# nrf7140_wificore register map
Vendor: Nordic Semiconductor; Series: nRF71; File version: 1
Registers are 32-bit, read-write, reset 0x0 unless marked. A register's access mark holds for its fields unless they carry their own. Offsets are from the block's base; [hi:lo] are bit positions; lines under a group give offsets from that group; {n}, {i} and the like mark numbered series.

## RPUMAC — WIFICore RPU MAC peripherals
Base 0x48080000
0x2000 CRYPTO_PERIP group — Unspecified
  0x00 MODE — CRYPTO PERIP MODE
    [0] CRYPTOMODE
      0=RX mode. Input is from MAC controller and output to EDC.; 1=TX mode. Input from EDC and output from MAC controller.
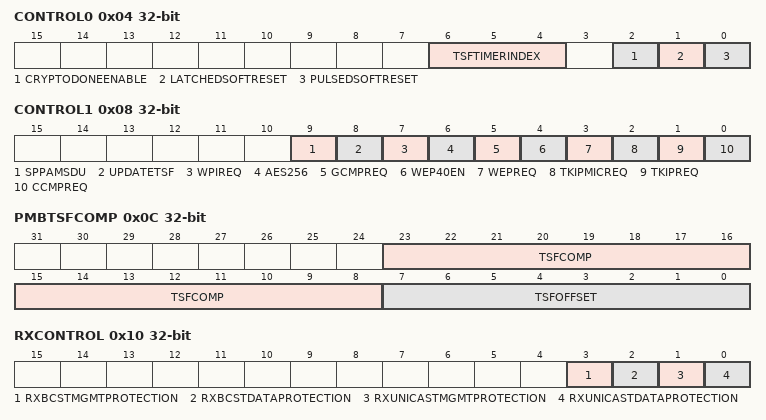
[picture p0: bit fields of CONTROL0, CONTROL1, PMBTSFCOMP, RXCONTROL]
  0x04 CONTROL0 — CRYPTO PERIP CONTROL 0
    [6:4] TSFTIMERINDEX — 64 bit timer index of hardware module. There are four 64 bit timers in and one of index is picked up for this.
    [2] CRYPTODONEENABLE — Enable EFS event CRYPTO_DONE_EVENT that indicates when the Crypto operation is complete.
      0=Disable CRYPTO_DONE_EVENT; 1=Enable CRYPTO_DONE_EVENT
    [1] LATCHEDSOFTRESET — Latched Crypto core soft reset.This bit is used to reset everything but the control registers.
      0=DeAssertResetToCore; 1=AssertResetToCore
    [0] PULSEDSOFTRESET — Self-clearing Crypto core soft reset.This bit is used to reset everything but the control registers.
      0=DeAssertResetToCore; 1=AssertResetToCore
  0x08 CONTROL1 ro — CRYPTO PERIP CONTROL 1
    [9] SPPAMSDU — Default value is zero, Set to 1 if SPP_A-MSDU_bit_setis requested by the receiver.
    [8] UPDATETSF — Set to 1 if HW is expected to modify TSF field in memcopy bytes. HW need read TSF value, compensate with COMP value and update in TSF field.
    [7] WPIREQ — WAPI operation
    [6] AES256 — Select AES key size.
      0=128Bits; 1=256Bits
    [5] GCMPREQ — GCMP operation
    [4] WEP40EN — WEP 40 operation
    [3] WEPREQ — WEP operation
    [2] TKIPMICREQ — TKIP Message Integrity Check (MIC) operation
    [1] TKIPREQ — TKIP operation
    [0] CCMPREQ — CCMP operation
  0x0C PMBTSFCOMP — PMB CRYPTO PERIP TSF COMP
    [23:8] TSFCOMP — Hw will add this value to TSF snapshot and update TSF value in probe response/beacon frame.
    [7:0] TSFOFFSET — TSF offset in memcopy stream.Must be set to a value greater than 1.
  0x10 RXCONTROL — CRYPTO PERIP RX CONTROL
    [3] RXBCSTMGMTPROTECTION — Set 1 to enable.
    [2] RXBCSTDATAPROTECTION — Set 1 to enable.
    [1] RXUNICASTMGMTPROTECTION — Set 1 to enable.
    [0] RXUNICASTDATAPROTECTION — Set 1 to enable.
  0x14 RXVECTORLENGTH — CRYPTO PERIP RX VECTOR LENGTH
    [7:0] RXVECTORLENGTH — RX vector length. Crypto hardware should bypass (memcopy) to output side without processing.
  0x18 RXFCSANDSTSLENGTH reset 0x5 — CRYPTO PERIP RX FCS AND STS LENGTH
    [7:0] RXFCSANDSTSLENGTH — Used to determine how many bytes need to be appended after decrypted payload.Note: When it's configured as 0, after payload bytes decrypted, controlstate machine will skip STEP_APPEND, do not appending any bytes.
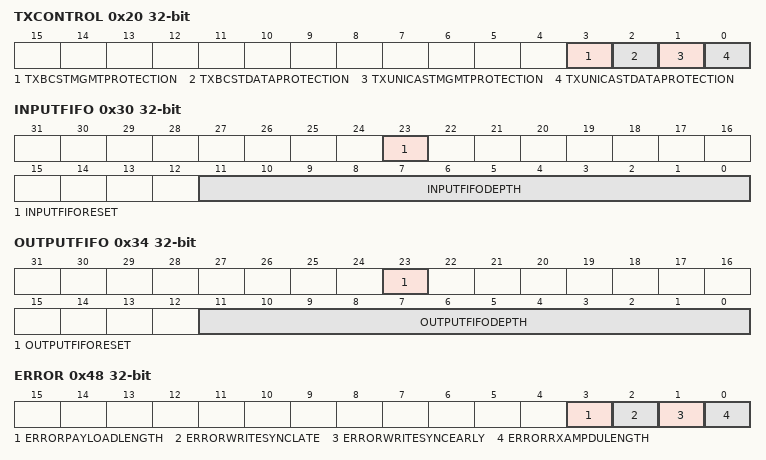
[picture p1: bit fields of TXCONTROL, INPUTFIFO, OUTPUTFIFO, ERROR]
  0x20 TXCONTROL — CRYPTO PERIP TX CONTROL
    [3] TXBCSTMGMTPROTECTION — Set 1 to enable.
    [2] TXBCSTDATAPROTECTION — Set 1 to enable.
    [1] TXUNICASTMGMTPROTECTION — Set 1 to enable.
    [0] TXUNICASTDATAPROTECTION — Set 1 to enable.
  0x24 TXVECTORLENGTH — CRYPTO PERIP TX VECTOR LENGTH
    [7:0] TXVECTORLENGTH — Valid range 0 to 255. Crypto hardware should bypass to output without processing.
  0x28 TXAMPDUSUBFRAMENUMBER reset 0x1 — CRYPTO PERIP TX AMPDU SUBFRAME NUMBER
    [6:0] TXAMPDUSUBFRAMENUMBER — Number of AMPDU subframes in current TX job.Minimum value is 1. Maximum value is 64.
  0x30 INPUTFIFO — CRYPTO PERIP INPUT FIFO
    [23] INPUTFIFORESET — Self-clearing input FIFO reset
      0=NoAction; 1=PerformReset
    [11:0] INPUTFIFODEPTH — Programmable FIFO depth.Note that DEPTH=0 will bypass the FIFO.Values of DEPTH greater than the physical FIFO depth will be saturated by hardware to the physical depth.
  0x34 OUTPUTFIFO — CRYPTO PERIP OUTPUT FIFO
    [23] OUTPUTFIFORESET — Self-clearing output FIFO reset
      0=NoAction; 1=PerformReset
    [11:0] OUTPUTFIFODEPTH — Programmable FIFO depth.Note that DEPTH=0 will bypass the FIFO.Values of DEPTH greater than the physical FIFO depth will be saturated by hardware to the physical depth.
  0x38 INPUTFIFOCOUNT ro — CRYPTO PERIP INPUT FIFO COUNT
    [11:0] INPUTFIFOCOUNT — Input FIFO data count.
  0x3C OUTPUTFIFOCOUNT ro — CRYPTO PERIP OUTPUT FIFO COUNT
    [11:0] OUTPUTFIFOCOUNT — Output FIFO data count.
  0x40 EVENTSTATUS — CRYPTO PERIP EVENT STATUS
    [0] CRYPTODONEEVENT — This bit is set to 1 when the Crypto operation is complete.Writing 1 sets this bit for test purposes.
  0x44 EVENTCLEAR — CRYPTO PERIP EVENT CLEAR
    [0] CRYPTODONECLEAR — Writing 1 to this bit sets CRYPTO_DONE and CRYPTO_DONE_EVENT to 0
  0x48 ERROR ro — CRYPTO PERIP ERROR
    [3] ERRORPAYLOADLENGTH — Received payload length is less than 0. Crypto will push valid=1 mask=1 eop=1 data=0 byte into the output, discard remaining inputs until sync flag received then start new job.
    [2] ERRORWRITESYNCLATE — TBus write sync flag appears later than expected. Crypto will set eop=1 on the last valid output byte, discard remaining inputs until sync flag received then start new job.
    [1] ERRORWRITESYNCEARLY — TBus write sync flag appears earlier than expected. Crypto will terminate current engine job if started, push valid=1 mask=1 eop=1 data=0 byte into the output, discard remaining inputs until sync flag received then start new job.
    [0] ERRORRXAMPDULENGTH — Received rx_ampdu_length is larger than 0xFFFF. Crypto will push valid=1 mask=1 eop=1 data=0 byte into the output, discard remaining inputs until sync flag received then start new job.
  0x4C ERRORCLEAR — CRYPTO PERIP ERROR CLEAR
    [0] CRYPTOPERIPERRORCLEAR — Writing 1 to this bit sets CRYPTO_PERIP_ERROR to 0
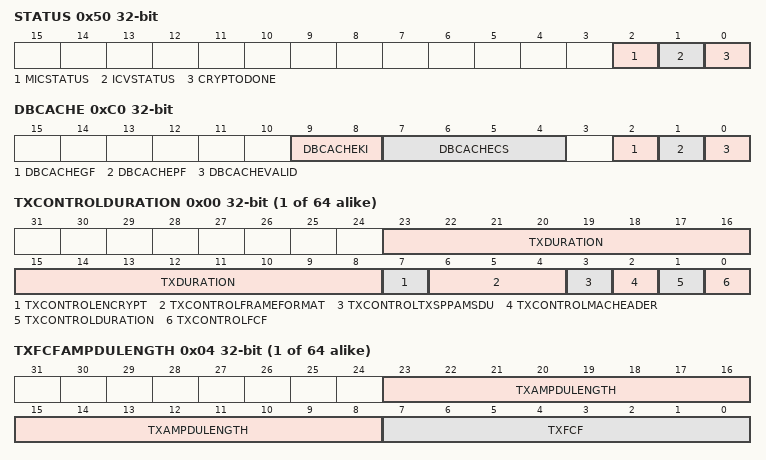
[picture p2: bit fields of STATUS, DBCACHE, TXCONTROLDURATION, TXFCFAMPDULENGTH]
  0x50 STATUS ro — CRYPTO PERIP STATUS
    [2] MICSTATUS — TKIP/CCMP/WAPI MIC status
      0=MicSuccess; 1=MicFail
    [1] ICVSTATUS — WEP ICV status
      0=IcvSuccess; 1=IcvFail
    [0] CRYPTODONE — Crypto operation done status. Writing CRYPTO_DONE_CLEAR=1 clears this status.
      0=Crypto operation not complete; 1=Crypto operation complete
  0x5C AADBLOCKS ro — CRYPTO PERIP AAD BLOCKS
    [11] AADBLOCKS — Number of valid AAD blocks:
      0=2AadBlocks; 1=3 AAD blocks (Only used by WAPI and GCMP operation)
  {0x38+4j} AAD{j} ro (j=10..14) — CRYPTO PERIP AAD1 {j-10}
    [23:0] AADATABLOCK{j} — Bytes {3j-28}:{3j-30} of AAD block 1.
  0x74 AAD15 ro — CRYPTO PERIP AAD1 5
    [7:0] AADATABLOCK15 — Byte 15 of AAD block 1.
  {0x28+4j} AAD{j} ro (j=20..24) — CRYPTO PERIP AAD2 {j-20}
    [23:0] AADATABLOCK{j} — Bytes {3j-58}:{3j-60} of AAD block 2.
  0x8C AAD25 ro — CRYPTO PERIP AAD2 5
    [7:0] AADATABLOCK25 — Byte 15 of AAD block 2.
  {0x18+4j} AAD{j} ro (j=30..34) — CRYPTO PERIP AAD3 {j-30}
    [23:0] AADATABLOCK{j} — Bytes {3j-88}:{3j-90} of AAD block 3.Used only for WAPI operation.
  0xA4 AAD35 ro — CRYPTO PERIP AAD3 5
    [7:0] AADATABLOCK35 — Byte 15 of AAD block 3.Used only for WAPI operation.
  {0xA8+4j} NONCE{j} ro (j=0..4) — CRYPTO PERIP NONCE {j}
    [23:0] NONCEVALUE{j} — Bytes {3j+2}:{3j} of the nonce value.For WAPI operation the entire 16 bytes are considered as the nonce value.For CCMP operation the lower 13 bytes are considered as the nonce value.
  0xBC NONCE5 ro — CRYPTO PERIP NONCE 5
    [7:0] NONCEVALUE5 — Byte 15 of the nonce value.For WAPI operation the entire 16 bytes are considered as the nonce value.For CCMP operation the lower 13 bytes are considered as the nonce value.
  0xC0 DBCACHE ro — CRYPTO PERIP DB CACHE
    [9:8] DBCACHEKI — Key ID
    [7:4] DBCACHECS — Cipher suite
    [2] DBCACHEGF — Grp_frm.
    [1] DBCACHEPF — Protected frame.
    [0] DBCACHEVALID — Cache valid. 1: Cache is valid. 0: Cache is invalid.
  0xC4 DBCACHEADDR10 ro — CRYPTO PERIP DB CACHE ADDR1 0
    [23:0] DBCACHEADDR10 — Bytes 2:0 of Addr1.
  0xC8 DBCACHEADDR11 ro — CRYPTO PERIP DB CACHE ADDR1 1
    [23:0] DBCACHEADDR11 — Bytes 5:3 of Addr1.
  0xCC DBCACHEADDR20 ro — CRYPTO PERIP DB CACHE ADDR2 0
    [23:0] DBCACHEADDR20 — Bytes 2:0 of Addr2.
  0xD0 DBCACHEADDR21 ro — CRYPTO PERIP DB CACHE ADDR2 1
    [23:0] DBCACHEADDR21 — Bytes 5:3 of Addr2.
  0xD4 DBCACHEBSSID0 ro — CRYPTO PERIP DB CACHE BSSID 0
    [23:0] DBCACHEBSSID0 — Bytes 2:0 of BSSID.
  0xD8 DBCACHEBSSID1 ro — CRYPTO PERIP DB CACHE BSSID 1
    [23:0] DBCACHEBSSID1 — Bytes 5:3 of BSSID.
  0xDC DBCACHEENABLE reset 0x1 — CRYPTO PERIP DB CACHE ENABLE
    [0] DBCACHEENABLE — Key search cache enable.
      0=Disable cache. Crypto will search new keys for each subframe.; 1=Enable cache. Crypto will use cached keys if search condition unchanged.
  0xE0 MIC0 ro — CRYPTO PERIP MIC 0
    [23:0] TKIPCALCMICVAL0 — Bytes 2:0 of the calculated Message Integrity Check (MIC) Bytes 2:0
  0xE4 MIC1 ro — CRYPTO PERIP MIC 1
    [23:0] TKIPCALCMICVAL1 — Bytes 5:3 of the calculated Message Integrity Check (MIC) Bytes 5:3
  0xE8 MIC2 ro — CRYPTO PERIP MIC 2
    [15:0] TKIPCALCMICVAL2 — Bytes 7:6 of the calculated Message Integrity Check (MIC) Bytes 7:6
  0xF0 TBUSRDMODE — CRYPTO PERIP TBUS RD MODE
    [1] TBUSDEBUGRDDISCARD — Discard PBus debug mode output (TBUS_DEBUG_RD_MODE=1):
      0=Output to PBus (debug mode); 1=DiscardOutput
  {0x100+8j} CRYPTOTXAMPDUSUBFRAMEPARAMS[{j}] (j=0..63) group — Unspecified
    0x00 TXCONTROLDURATION — Description cluster: TX CONTROL DURATION
      [23:8] TXDURATION — Replace duration field of MAC header with this configuration.
      [7] TXCONTROLENCRYPT — Encrypt enable
      [6:4] TXCONTROLFRAMEFORMAT — Frame format
      [3] TXCONTROLTXSPPAMSDU — TX_SPP_A_MSDU
      [2] TXCONTROLMACHEADER — Set to 1 to populate TSF in mac header
      [1] TXCONTROLDURATION — Set to 1 to update Duration
      [0] TXCONTROLFCF — Set to 1 to update FCF
    0x04 TXFCFAMPDULENGTH — Description cluster: TX FCF AMPDU LENGTH
      [23:8] TXAMPDULENGTH — AMPDU subframe length. Includes MAC header, security header and payload.Security tail bytes are not included in this length.
      [7:0] TXFCF — This is used to set some bits in frame control field by hardware (retry bit).Hardware should do bitwise 'OR' operation on first byte of MAC header.
  {0x300+0x1C*j} CRYPTOVIFKEYDB[{j}] (j=0..3) group — Unspecified
    0x00 VIFDBVALID — Description cluster: VIF DB VALID
      [0] VIFDBVALID — DB is valid when set.
    0x04 VIFBSSID0 — Description cluster: VIF BSSID 0
      [23:0] VIFBSSID0 — VIF connected BSSID[23:0].Note: Value is valid only when VIF_DB_VALID is set.
    0x08 VIFBSSID1 — Description cluster: VIF BSSID 1
      [23:0] VIFBSSID1 — VIF connected BSSID[47:24].Note: Value is valid only when VIF_DB_VALID is set.
    0x0C VIFADDR0 — Description cluster: VIF ADDR 0
      [23:0] VIFADDR0 — Virtual interface MAC address[23:0].Note: Value is valid only when VIF_DB_VALID is set.
    0x10 VIFADDR1 — Description cluster: VIF ADDR 1
      [23:0] VIFADDR1 — Virtual interface MAC address[47:24].Note: Value is valid only when VIF_DB_VALID is set.
    0x14 VIFKEYVALID — Description cluster: VIF KEY VALID
      [3:0] VIFKEYVALID — Bit[0]: Key 0 ValidBit[1]: Key 1 ValidBit[2]: Key 2 ValidBit[3]: Key 3 ValidNote: Value is valid only when VIF_DB_VALID is set.
    0x18 VIFCIPHERSUITE — Description cluster: VIF CIPHER SUITE
      [7:0] VIFCIPHERSUITE — 0: Plain1: WEP 402: WEP 1043: TKIP Only4: TKIP and MIC5: CCMP_1286: CCMP_2567: GCMP_1288: GCMP_2569: WAPINote: Value is valid only when VIF_DB_VALID is set.
  {0x400+0x20*j} CRYPTOPEERKEYDB[{j}] (j=0..7) group — Unspecified
    0x00 PEERDBVALID — Description cluster: PEER DB VALID
      [0] PEERDBVALID — DB is valid when set.
    0x04 PEERADDR0 — Description cluster: PEER ADDR 0
      [23:0] PEERADDR0 — Peer MAC address[23:0].Note: Value is valid only when PEER_DB_VALID is set.
    0x08 PEERADDR1 — Description cluster: PEER ADDR 1
      [23:0] PEERADDR1 — Peer MAC address[47:24].Note: Value is valid only when PEER_DB_VALID is set.
    0x0C PEERVIFADDR0 — Description cluster: PEER VIF ADDR 0
      [23:0] PEERVIFADDR0 — Virtual interface MAC address[23:0].Note: Value is valid only when PEER_DB_VALID is set.
    0x10 PEERVIFADDR1 — Description cluster: PEER VIF ADDR 1
      [23:0] PEERVIFADDR1 — Virtual interface MAC address[47:24].Note: Value is valid only when PEER_DB_VALID is set.
    0x14 PEERKEYVALID — Description cluster: PEER KEY VALID
      [1:0] PEERKEYVALID — Bit[0]: Unicast Key validBit[1]: Broadcast Key validNote: Value is valid only when PEER_DB_VALID is set.
    0x18 UCSTCIPHERSUITE — Description cluster: UCST CIPHER SUITE
      [7:0] UCSTCIPHERSUITE — 0: Plain1: WEP 402: WEP 1043: TKIP Only4: TKIP and MIC5: CCMP_1286: CCMP_2567: GCMP_1288: GCMP_2569: WAPINote: Value is valid only when PEER_DB_VALID is set.
    0x1C BCSTCIPHERSUITE — Description cluster: BCST CIPHER SUITE
      [7:0] BCSTCIPHERSUITE — 0: Plain1: WEP 402: WEP 1043: TKIP Only4: TKIP and MIC5: CCMP_1286: CCMP_2567: GCMP_1288: GCMP_2569: WAPINote: Value is valid only when PEER_DB_VALID is set.
0x4000 WLAN_MAC_CTRL group — Unspecified
  0x00 PULSEDSOFTWARERESET — WLAN MAC CTRL PULSED SOFTWARE RESET
    [0] WLANMACCTRLPULSEDSOFTWARERESET
  0x04 LATCHEDSOFTWARERESET — WLAN MAC CTRL LATCHED SOFTWARE RESET
    [0] WLANMACCTRLLATCHEDSOFTWARERESET
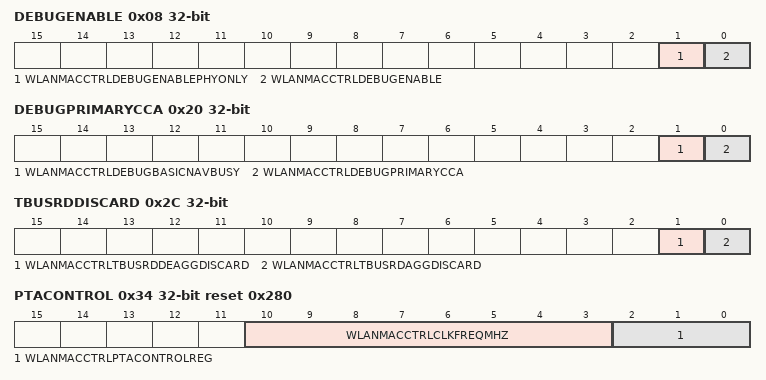
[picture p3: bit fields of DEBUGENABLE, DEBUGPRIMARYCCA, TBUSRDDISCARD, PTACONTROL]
  0x08 DEBUGENABLE — WLAN MAC CTRL DEBUG ENABLE
    [1] WLANMACCTRLDEBUGENABLEPHYONLY — Override TX_ABORT, TX_END, TX_END_STATUS and PRIMARY_CCA using debug registers
    [0] WLANMACCTRLDEBUGENABLE — Override TX_ABORT, EDCA_EVENT, EDCA_EVENT_STATUS, TX_END, TX_END_STATUS and PRIMARY_CCA using debug registers
  0x0C DEBUGWLANTXABORT — WLAN MAC CTRL DEBUG WLAN TX ABORT
    [0] WLANMACCTRLDEBUGWLANTXABORT
  0x10 DEBUGEDCAEVENT — WLAN MAC CTRL DEBUG EDCA EVENT
    [0] WLANMACCTRLDEBUGEDCAEVENT
  0x14 DEBUGEDCAEVENTSTATUS — WLAN MAC CTRL DEBUG EDCA EVENT STATUS
    [4:0] WLANMACCTRLDEBUGEDCAEVENTSTATUS
  0x18 DEBUGTXEND — WLAN MAC CTRL DEBUG TX END
    [0] WLANMACCTRLDEBUGTXEND
  0x1C DEBUGTXENDSTATUS — WLAN MAC CTRL DEBUG TX END STATUS
    [0] WLANMACCTRLDEBUGTXENDSTATUS
  0x20 DEBUGPRIMARYCCA — WLAN MAC CTRL DEBUG PRIMARY CCA
    [1] WLANMACCTRLDEBUGBASICNAVBUSY, [0] WLANMACCTRLDEBUGPRIMARYCCA
  0x24 IGNOREDEAGGWRSYNC — WLAN MAC CTRL IGNORE DEAGG WR SYNC
    [0] WLANMACCTRLIGNOREDEAGGWRSYNC
  0x28 FSMSTATE ro — WLAN MAC CTRL FSM STATE
    [1:0] WLANMACCTRLFSMSTATE — MAC Controller FSM State:
      0=Idle; 1=Rx; 2=Tx; 3=Inactive
  0x2C TBUSRDDISCARD — WLAN MAC CTRL TBUS RD DISCARD
    [1] WLANMACCTRLTBUSRDDEAGGDISCARD — Discard deaggregation TBus read port:
      0=DonTDiscard; 1=Discard
    [0] WLANMACCTRLTBUSRDAGGDISCARD — Discard aggregation TBus read port:
      0=DonTDiscard; 1=Discard
  0x30 DEACTIVATE — WLAN MAC CTRL DEACTIVATE
    [1:0] WLANMACCTRLDEACTIVATE — Deactivate MAC and disable the PHY:
      0=DonTDeactivate; 1=Deactivate safely when FSM state is IDLE; 2=Deactivate forcefully regardless of FSM state; 3=Reserve (This is reserved.)
  0x34 PTACONTROL reset 0x280 — WLAN MAC CTRL PTA CONTROL
    [10:3] WLANMACCTRLCLKFREQMHZ — Clock frequency in MHz
    [2:0] WLANMACCTRLPTACONTROLREG — PTA control register:bit 0 : Enable AGG TX requestbit 1 : Enable DEAGG RX requestbit 2 : Enable PHY RX request
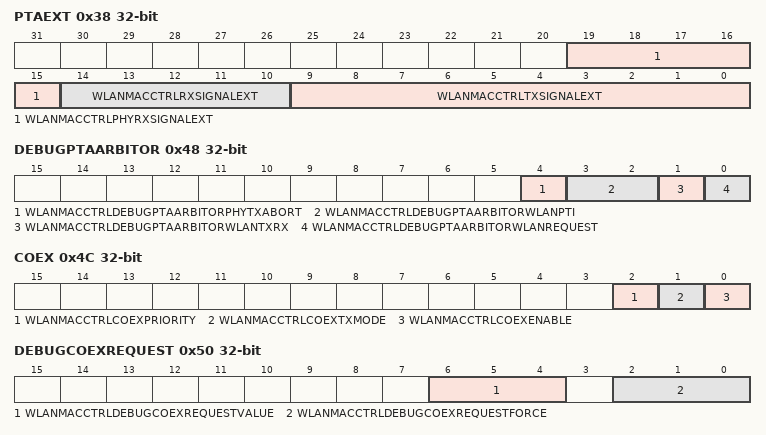
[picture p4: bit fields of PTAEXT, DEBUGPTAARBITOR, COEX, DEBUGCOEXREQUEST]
  0x38 PTAEXT — WLAN MAC CTRL PTA EXT
    [19:15] WLANMACCTRLPHYRXSIGNALEXT — Duration by which PHY_RX_REQUEST signal is extended in microseconds
    [14:10] WLANMACCTRLRXSIGNALEXT — Duration by which DEAGG_RX_REQUEST signal is extended in microseconds
    [9:0] WLANMACCTRLTXSIGNALEXT — Duration by which AGG_TX_REQUEST signal is extended in microseconds
  0x3C TXABORTTIMEOUT — WLAN MAC CTRL TX ABORT TIMEOUT
    [9:0] WLANMACCTRLTXABORTTIMEOUT — Ignore WLAN_TX_ABORT signal from PTA if asserted after this timeout, counter running at core clock.
  0x40 DEBUGBEAMFORMINGDMALENGTH wo — WLAN MAC CTRL DEBUG BEAMFORMING DMA LENGTH
    [8:0] WLANMACCTRLDEBUGBEAMFORMINGDMALENGTH — Writing to this register triggers a beamforming DMA length update
  0x44 DEBUGBEAMFORMINGSNR wo — WLAN MAC CTRL DEBUG BEAMFORMING SNR
    [7:0] WLANMACCTRLDEBUGBEAMFORMINGSNR — Writing to this register triggers a beamforming SNR update
  0x48 DEBUGPTAARBITOR ro — WLAN MAC CTRL DEBUG PTA ARBITOR
    [4] WLANMACCTRLDEBUGPTAARBITORPHYTXABORT — Debug wlan_request output from pta_arbitor
    [3:2] WLANMACCTRLDEBUGPTAARBITORWLANPTI — Debug wlan_request output from pta_arbitor
    [1] WLANMACCTRLDEBUGPTAARBITORWLANTXRX — Debug wlan_request output from pta_arbitor
    [0] WLANMACCTRLDEBUGPTAARBITORWLANREQUEST — Debug wlan_request output from pta_arbitor
  0x4C COEX — WLAN MAC CTRL COEX
    [2] WLANMACCTRLCOEXPRIORITY — Coexistence priority:
      0=WiFiHasPriority; 1=BtHasPriority
    [1] WLANMACCTRLCOEXTXMODE — TX request applies to:
      0=5GhzOnly; 1=245Ghz
    [0] WLANMACCTRLCOEXENABLE — Enable coexistence support
  0x50 DEBUGCOEXREQUEST — WLAN MAC CTRL DEBUG COEX REQUEST
    [6:4] WLANMACCTRLDEBUGCOEXREQUESTVALUE — Force coexistence request output to this value when WLAN_MAC_CTRL_DEBUG_COEX_REQUEST_FORCE[i] is set
    [2:0] WLANMACCTRLDEBUGCOEXREQUESTFORCE — Force coexistence request output with value WLAN_MAC_CTRL_DEBUG_COEX_REQUEST_VALUE[i]
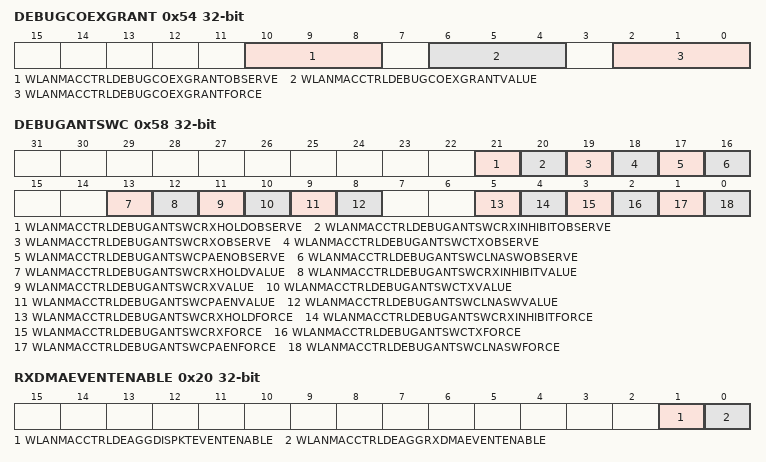
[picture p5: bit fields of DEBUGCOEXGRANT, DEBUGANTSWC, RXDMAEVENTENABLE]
  0x54 DEBUGCOEXGRANT — WLAN MAC CTRL DEBUG COEX GRANT
    [10:8] WLANMACCTRLDEBUGCOEXGRANTOBSERVE — Observe coexistence grant input
    [6:4] WLANMACCTRLDEBUGCOEXGRANTVALUE — Force coexistence grant input to this value when WLAN_MAC_CTRL_DEBUG_COEX_GRANT_FORCE[i] is set
    [2:0] WLANMACCTRLDEBUGCOEXGRANTFORCE — Force coexistence grant input with value WLAN_MAC_CTRL_DEBUG_COEX_GRANT_VALUE[i]
  0x58 DEBUGANTSWC — WLAN MAC CTRL DEBUG ANTSWC
    [21] WLANMACCTRLDEBUGANTSWCRXHOLDOBSERVE — Observe antenna switch controller RX hold input
    [20] WLANMACCTRLDEBUGANTSWCRXINHIBITOBSERVE — Observe antenna switch controller RX inhibit input
    [19] WLANMACCTRLDEBUGANTSWCRXOBSERVE — Observe antenna switch controller RX input
    [18] WLANMACCTRLDEBUGANTSWCTXOBSERVE — Observe antenna switch controller TX input
    [17] WLANMACCTRLDEBUGANTSWCPAENOBSERVE — Observe antenna switch controller power amplifier enable input
    [16] WLANMACCTRLDEBUGANTSWCLNASWOBSERVE — Observe antenna switch controller LNA switch input
    [13] WLANMACCTRLDEBUGANTSWCRXHOLDVALUE — Force antenna switch controller RX hold input to this value when WLAN_MAC_CTRL_DEBUG_ANTSWC_RX_HOLD_FORCE is set
    [12] WLANMACCTRLDEBUGANTSWCRXINHIBITVALUE — Force antenna switch controller RX inhibit input to this value when WLAN_MAC_CTRL_DEBUG_ANTSWC_RX_INHIBIT_FORCE is set
    [11] WLANMACCTRLDEBUGANTSWCRXVALUE — Force antenna switch controller RX input to this value when WLAN_MAC_CTRL_DEBUG_ANTSWC_RX_FORCE is set
    [10] WLANMACCTRLDEBUGANTSWCTXVALUE — Force antenna switch controller TX input to this value when WLAN_MAC_CTRL_DEBUG_ANTSWC_TX_FORCE is set
    [9] WLANMACCTRLDEBUGANTSWCPAENVALUE — Force antenna switch controller power amplifier enable input to this value when WLAN_MAC_CTRL_DEBUG_ANTSWC_PA_EN_FORCE is set
    [8] WLANMACCTRLDEBUGANTSWCLNASWVALUE — Force antenna switch controller LNA switch input to this value when WLAN_MAC_CTRL_DEBUG_ANTSWC_LNA_SW_FORCE is set
    [5] WLANMACCTRLDEBUGANTSWCRXHOLDFORCE — Force antenna switch controller RX hold input with value WLAN_MAC_CTRL_DEBUG_ANTSWC_RX_HOLD_VALUE
    [4] WLANMACCTRLDEBUGANTSWCRXINHIBITFORCE — Force antenna switch controller RX inhibit input with value WLAN_MAC_CTRL_DEBUG_ANTSWC_RX_INHIBIT_VALUE
    [3] WLANMACCTRLDEBUGANTSWCRXFORCE — Force antenna switch controller RX input with value WLAN_MAC_CTRL_DEBUG_ANTSWC_RX_VALUE
    [2] WLANMACCTRLDEBUGANTSWCTXFORCE — Force antenna switch controller TX input with value WLAN_MAC_CTRL_DEBUG_ANTSWC_TX_VALUE
    [1] WLANMACCTRLDEBUGANTSWCPAENFORCE — Force antenna switch controller power amplifier enable input with value WLAN_MAC_CTRL_DEBUG_ANTSWC_PA_EN_VALUE
    [0] WLANMACCTRLDEBUGANTSWCLNASWFORCE — Force antenna switch controller LNA switch input with value WLAN_MAC_CTRL_DEBUG_ANTSWC_LNA_SW_VALUE
0xE000 WLAN_MAC_CTRL_DEAGG group — Unspecified
  0x00 PULSEDRESET — WLAN MAC CTRL DEAGG PULSED RESET
    [0] WLANMACCTRLDEAGGPULSEDRESET
  0x04 LATCHEDRESET — WLAN MAC CTRL DEAGG LATCHED RESET
    [0] WLANMACCTRLDEAGGLATCHEDRESET
  0x08 OFDMSIFSVALUE — WLAN MAC CTRL DEAGG OFDM SIFS VALUE
    [23:0] WLANMACCTRLDEAGGOFDMSIFSVALUE
  0x0C DSSSSIFSVALUE — WLAN MAC CTRL DEAGG DSSS SIFS VALUE
    [23:0] WLANMACCTRLDEAGGDSSSSIFSVALUE
  0x10 INTRCOALSESIZE — WLAN MAC CTRL DEAGG INTR COALSE SIZE
    [23:0] WLANMACCTRLDEAGGINTRCOALSESIZE
  0x14 INTRCOALSENUM — WLAN MAC CTRL DEAGG INTR COALSE NUM
    [7:0] WLANMACCTRLDEAGGINTRCOALSENUM
  0x18 PHYRXVECTCNT reset 0x4E — WLAN MAC CTRL DEAGG PHY RX VECT CNT
    [6:0] WLANMACCTRLDEAGGPHYRXVECTCNT
  0x1C MACRXVECTCNT reset 0x8 — WLAN MAC CTRL DEAGG MAC RX VECT CNT
    [6:0] WLANMACCTRLDEAGGMACRXVECTCNT
  0x20 RXDMAEVENTENABLE — WLAN MAC CTRL DEAGG RX DMA EVENT ENABLE
    [1] WLANMACCTRLDEAGGDISPKTEVENTENABLE, [0] WLANMACCTRLDEAGGRXDMAEVENTENABLE
  0x24 RXDMAEVENTCLEAR — WLAN MAC CTRL DEAGG RX DMA EVENT CLEAR
    [0] WLANMACCTRLDEAGGRXDMAEVENTCLEAR
  0x28 RXDMALENGTH ro — WLAN MAC CTRL DEAGG RX DMA LENGTH
    [23:0] WLANMACCTRLDEAGGRXDMALENGTH
  0x2C VIFCONTROL — WLAN MAC CTRL DEAGG VIF CONTROL
    [3:0] WLANMACCTRLDEAGGVIFCONTROL — The Deagg module has support for 4 VIF addresses.Firmware is expected to set the corresponding valid flag hereafter configuring each VIF address.Bit 0 (LSB) : VIF 0 validBit 1 : VIF 1 validBit 2 : VIF 2 validBit 3 (MSB) : VIF 3 valid
  0x30 MACADDR00 — WLAN MAC CTRL DEAGG MAC ADDR 0 0
    [23:0] WLANMACCTRLDEAGGMACADDR00
  0x34 MACADDR01 — WLAN MAC CTRL DEAGG MAC ADDR 0 1
    [23:0] WLANMACCTRLDEAGGMACADDR01
  0x38 MACADDR10 — WLAN MAC CTRL DEAGG MAC ADDR 1 0
    [23:0] WLANMACCTRLDEAGGMACADDR10
  0x3C MACADDR11 — WLAN MAC CTRL DEAGG MAC ADDR 1 1
    [23:0] WLANMACCTRLDEAGGMACADDR11
  0x40 MACADDR20 — WLAN MAC CTRL DEAGG MAC ADDR 2 0
    [23:0] WLANMACCTRLDEAGGMACADDR20
  0x44 MACADDR21 — WLAN MAC CTRL DEAGG MAC ADDR 2 1
    [23:0] WLANMACCTRLDEAGGMACADDR21
  0x48 MACADDR30 — WLAN MAC CTRL DEAGG MAC ADDR 3 0
    [23:0] WLANMACCTRLDEAGGMACADDR30
  0x4C MACADDR31 — WLAN MAC CTRL DEAGG MAC ADDR 3 1
    [23:0] WLANMACCTRLDEAGGMACADDR31
  0x50 AMPDUBITMAPINBYTES — WLAN MAC CTRL DEAGG AMPDU BITMAP IN BYTES
    [5:0] WLANMACCTRLDEAGGAMPDUBITMAPINBYTES
  0x54 AMPDUBITMAPSIZE — WLAN MAC CTRL DEAGG AMPDU BITMAP SIZE
    [8:0] WLANMACCTRLDEAGGAMPDUBITMAPSIZE
  0x58 MAXQOSTIDS — WLAN MAC CTRL DEAGG MAX QOS TIDS
    [4:0] WLANMACCTRLDEAGGMAXQOSTIDS
  0x5C CLEARALLDEBUGCNTS — WLAN MAC CTRL DEAGG CLEAR ALL DEBUG CNTS
    [0] WLANMACCTRLDEAGGCLEARALLDEBUGCNTS
  0x60 FSMSTATE ro — WLAN MAC CTRL DEAGG FSM STATE
    [3:0] WLANMACCTRLDEAGGFSMSTATE — Deaggregation FSM State:
      0=Idle; 1=RcvRxVector; 2=GenDmaEvent; 3=SEND_RX_VECTOR_TO_MAC; 4=ProcessAmpduFrame; 5=ProcessMpduFrame; 6=AppendCrcStatus; 7=DiscardFrame; 8=GenEop; 9=SkipPadBytes; 10=WaitForSifs
  0x64 RXSTARTCNT ro — WLAN MAC CTRL DEAGG RX START CNT
    [23:0] WLANMACCTRLDEAGGRXSTARTCNT
  0x68 VALIDPHYVECTORCNT ro — WLAN MAC CTRL DEAGG VALID PHY VECTOR CNT
    [23:0] WLANMACCTRLDEAGGVALIDPHYVECTORCNT
  0x6C INVALIDPHYVECTORCNT ro — WLAN MAC CTRL DEAGG INVALID PHY VECTOR CNT
    [23:0] WLANMACCTRLDEAGGINVALIDPHYVECTORCNT
  0x70 AMPDURCVDCNT ro — WLAN MAC CTRL DEAGG AMPDU RCVD CNT
    [23:0] WLANMACCTRLDEAGGAMPDURCVDCNT
  0x74 MPDURCVDCNT ro — WLAN MAC CTRL DEAGG MPDU RCVD CNT
    [23:0] WLANMACCTRLDEAGGMPDURCVDCNT
  0x78 CRC32PASSCNT ro — WLAN MAC CTRL DEAGG CRC32PASS CNT
    [23:0] WLANMACCTRLDEAGGCRC32PASSCNT
  0x7C CRC32FAILCNT ro — WLAN MAC CTRL DEAGG CRC32FAIL CNT
    [23:0] WLANMACCTRLDEAGGCRC32FAILCNT
  0x80 CRC8PASSCNT ro — WLAN MAC CTRL DEAGG CRC8PASS CNT
    [23:0] WLANMACCTRLDEAGGCRC8PASSCNT
  0x84 CRC8FAILCNT ro — WLAN MAC CTRL DEAGG CRC8FAIL CNT
    [23:0] WLANMACCTRLDEAGGCRC8FAILCNT
  0x88 UNICASTPKTCNT ro — WLAN MAC CTRL DEAGG UNICAST PKT CNT
    [23:0] WLANMACCTRLDEAGGUNICASTPKTCNT
  0x8C BRDCSTPKTCNT ro — WLAN MAC CTRL DEAGG BRDCST PKT CNT
    [23:0] WLANMACCTRLDEAGGBRDCSTPKTCNT
  0x90 TRIGGERDMACNT ro — WLAN MAC CTRL DEAGG TRIGGER DMA CNT
    [23:0] WLANMACCTRLDEAGGTRIGGERDMACNT
  0x94 GENEOPCNT ro — WLAN MAC CTRL DEAGG GEN EOP CNT
    [23:0] WLANMACCTRLDEAGGGENEOPCNT
  0x98 SIFSFRMCNT ro — WLAN MAC CTRL DEAGG SIFS FRM CNT
    [23:0] WLANMACCTRLDEAGGSIFSFRMCNT
  0x9C RESPONSEFRMCNT ro — WLAN MAC CTRL DEAGG RESPONSE FRM CNT
    [23:0] WLANMACCTRLDEAGGRESPONSEFRMCNT
  0xA0 RCVDCTSCNT ro — WLAN MAC CTRL DEAGG RCVD CTS CNT
    [23:0] WLANMACCTRLDEAGGRCVDCTSCNT
  0xA4 RCVDRTSCNT ro — WLAN MAC CTRL DEAGG RCVD RTS CNT
    [23:0] WLANMACCTRLDEAGGRCVDRTSCNT
  0xA8 RCVDCNTRLPKTCNT ro — WLAN MAC CTRL DEAGG RCVD CNTRL PKT CNT
    [23:0] WLANMACCTRLDEAGGRCVDCNTRLPKTCNT
  0xAC RCVDMGMTPKTCNT ro — WLAN MAC CTRL DEAGG RCVD MGMT PKT CNT
    [23:0] WLANMACCTRLDEAGGRCVDMGMTPKTCNT
  0xB0 RCVDQOSDATAPKTCNT ro — WLAN MAC CTRL DEAGG RCVD QOS DATA PKT CNT
    [23:0] WLANMACCTRLDEAGGRCVDQOSDATAPKTCNT
  0xB4 RCVDNONQOSDATAPKTCNT ro — WLAN MAC CTRL DEAGG RCVD NON QOS DATA PKT CNT
    [23:0] WLANMACCTRLDEAGGRCVDNONQOSDATAPKTCNT
  0xB8 DSSSCRC32PASSCNT ro — WLAN MAC CTRL DEAGG DSSS CRC32PASS CNT
    [23:0] WLANMACCTRLDEAGGDSSSCRC32PASSCNT
  0xBC DSSSCRC32FAILCNT ro — WLAN MAC CTRL DEAGG DSSS CRC32FAIL CNT
    [23:0] WLANMACCTRLDEAGGDSSSCRC32FAILCNT
  0xC0 CRNTPKTLENPHYVECTOR ro — WLAN MAC CTRL DEAGG CRNT PKT LEN PHY VECTOR
    [23:0] WLANMACCTRLDEAGGCRNTPKTLENPHYVECTOR
  0xC4 CRNTPKTAMPDUORMPDU ro — WLAN MAC CTRL DEAGG CRNT PKT AMPDU OR MPDU
    [0] WLANMACCTRLDEAGGCRNTPKTAMPDUORMPDU
  0xC8 CRNTAMPDUSUBFRMRCVDCNT ro — WLAN MAC CTRL DEAGG CRNT AMPDU SUB FRM RCVD CNT
    [23:0] WLANMACCTRLDEAGGCRNTAMPDUSUBFRMRCVDCNT
  0xCC CRNTPKTSUBFRMLEN ro — WLAN MAC CTRL DEAGG CRNT PKT SUB FRM LEN
    [23:0] WLANMACCTRLDEAGGCRNTPKTSUBFRMLEN
  0xD0 CRNTPKTCRCSTATUS ro — WLAN MAC CTRL DEAGG CRNT PKT CRC STATUS
    [0] WLANMACCTRLDEAGGCRNTPKTCRCSTATUS
  0xD4 CRNTPKTFCF ro — WLAN MAC CTRL DEAGG CRNT PKT FCF
    [15:0] WLANMACCTRLDEAGGCRNTPKTFCF
  0xD8 CRNTPKTRCVDMPDUBYTECNT ro — WLAN MAC CTRL DEAGG CRNT PKT RCVDMPDUBYTECNT
    [23:0] WLANMACCTRLDEAGGCRNTPKTRCVDMPDUBYTECNT
  0xDC CRNTPKTSEQNUM ro — WLAN MAC CTRL DEAGG CRNT PKT SEQ NUM
    [11:0] WLANMACCTRLDEAGGCRNTPKTSEQNUM
  0xE0 STARTSEQNUM ro — WLAN MAC CTRL DEAGG START SEQ NUM
    [11:0] WLANMACCTRLDEAGGSTARTSEQNUM
  0xE4 DMALENPRGMD ro — WLAN MAC CTRL DEAGG DMA LEN PRGMD
    [23:0] WLANMACCTRLDEAGGDMALENPRGMD
  0xE8 DMAPENDINGBYTES ro — WLAN MAC CTRL DEAGG DMA PENDING BYTES
    [23:0] WLANMACCTRLDEAGGDMAPENDINGBYTES
  0xEC DMASENTBYTESCNT ro — WLAN MAC CTRL DEAGG DMA SENT BYTES CNT
    [23:0] WLANMACCTRLDEAGGDMASENTBYTESCNT
  0xF0 BARCONTROLFIELD ro — WLAN MAC CTRL DEAGG BAR CONTROL FIELD
    [15:0] WLANMACCTRLDEAGGBARCONTROLFIELD
  0xF4 LASTPKTLENPHYVECTOR ro — WLAN MAC CTRL DEAGG LAST PKT LEN PHY VECTOR
    [23:0] WLANMACCTRLDEAGGLASTPKTLENPHYVECTOR
  0xF8 LASTPKTSUBFRMLEN ro — WLAN MAC CTRL DEAGG LAST PKT SUB FRM LEN
    [23:0] WLANMACCTRLDEAGGLASTPKTSUBFRMLEN
  0xFC LASTPKTAMPDUORMPDU ro — WLAN MAC CTRL DEAGG LAST PKT AMPDU OR MPDU
    [0] WLANMACCTRLDEAGGLASTPKTAMPDUORMPDU
  0x100 LASTAMPDUSUBFRMRCVDCNT ro — WLAN MAC CTRL DEAGG LAST AMPDU SUB FRM RCVD CNT
    [23:0] WLANMACCTRLDEAGGLASTAMPDUSUBFRMRCVDCNT
  0x104 LASTPKTCRCSTATUS ro — WLAN MAC CTRL DEAGG LAST PKT CRC STATUS
    [0] WLANMACCTRLDEAGGLASTPKTCRCSTATUS
  0x108 LASTPKTFCF ro — WLAN MAC CTRL DEAGG LAST PKT FCF
    [15:0] WLANMACCTRLDEAGGLASTPKTFCF
  0x10C FEATUREENABLE — WLAN MAC CTRL DEAGG FEATURE ENABLE
    [16:0] WLANMACCTRLDEAGGFEATUREENABLE
  {0x110+8j} VIF{j}BSSID0 (j=0..3) — WLAN MAC CTRL DEAGG VIF{j} BSSID 0
    [23:0] WLANMACCTRLDEAGGVIF{j}BSSID0
  {0x114+8j} VIF{j}BSSID1 (j=0..3) — WLAN MAC CTRL DEAGG VIF{j} BSSID 1
    [23:0] WLANMACCTRLDEAGGVIF{j}BSSID1
  {0x130+4j} VIF{j}STAAID (j=0..3) — WLAN MAC CTRL DEAGG VIF{j} STA AID
    [11:0] WLANMACCTRLDEAGGVIF{j}STAAID
  0x140 DEBUGHETRIGGERPKTCNT ro — WLAN MAC CTRL DEAGG DEBUG HE TRIGGER PKT CNT
    [23:0] WLANMACCTRLDEAGGDEBUGHETRIGGERPKTCNT
  0x144 DEBUGHETRIGGERPKTAIDMATCHEDCNT ro — WLAN MAC CTRL DEAGG DEBUG HE TRIGGER PKT AID MATCHED CNT
    [23:0] WLANMACCTRLDEAGGDEBUGHETRIGGERPKTAIDMATCHEDCNT
  0x148 DEBUGHEBASICTRIGGERPKTCNT ro — WLAN MAC CTRL DEAGG DEBUG HE BASIC TRIGGER PKT CNT
    [23:0] WLANMACCTRLDEAGGDEBUGHEBASICTRIGGERPKTCNT
  0x14C DEBUGHEMURTSCNT ro — WLAN MAC CTRL DEAGG DEBUG HE MU RTS CNT
    [23:0] WLANMACCTRLDEAGGDEBUGHEMURTSCNT
  0x150 DEBUGHEMULTISTABACNT ro — WLAN MAC CTRL DEAGG DEBUG HE MULTI STA BA CNT
    [23:0] WLANMACCTRLDEAGGDEBUGHEMULTISTABACNT
  0x154 DEBUGHEMUBARCNT ro — WLAN MAC CTRL DEAGG DEBUG HE MU BAR CNT
    [23:0] WLANMACCTRLDEAGGDEBUGHEMUBARCNT
  0x158 DEBUGHEBSRPCNT ro — WLAN MAC CTRL DEAGG DEBUG HE BSRP CNT
    [23:0] WLANMACCTRLDEAGGDEBUGHEBSRPCNT
  0x15C BTCOEXCTRL — WLAN MAC CTRL DEAGG BT COEX CTRL
    [1:0] WLANMACCTRLDEAGGBTCOEXCTRL
  0x160 RXVECTTXOP ro — WLAN MAC CTRL DEAGG RX VECT TXOP
    [6:0] WLANMACCTRLDEAGGRXVECTTXOP
  0x164 DISPKTEVENTCLEAR — WLAN MAC CTRL DEAGG DIS PKT EVENT CLEAR
    [0] WLANMACCTRLDEAGGDISPKTEVENTCLEAR
  0x168 DEFAULTSIFSVALUE — WLAN MAC CTRL DEAGG DEFAULT SIFS VALUE
    [23:0] WLANMACCTRLDEAGGDEFAULTSIFSVALUE
  0x16C DEBUGNDPARECEIVEDCNT ro — WLAN MAC CTRL DEAGG DEBUG NDPA RECEIVED CNT
    [23:0] WLANMACCTRLDEAGGDEBUGNDPARECEIVEDCNT
  0x170 DEBUGPROCESSNDPCNT ro — WLAN MAC CTRL DEAGG DEBUG PROCESS NDP CNT
    [23:0] WLANMACCTRLDEAGGDEBUGPROCESSNDPCNT
  0x174 DEBUGVHTNDPARECEIVEDCNT ro — WLAN MAC CTRL DEAGG DEBUG VHT NDPA RECEIVED CNT
    [23:0] WLANMACCTRLDEAGGDEBUGVHTNDPARECEIVEDCNT
  0x178 DEBUGHENDPARECEIVEDCNT ro — WLAN MAC CTRL DEAGG DEBUG HE NDPA RECEIVED CNT
    [23:0] WLANMACCTRLDEAGGDEBUGHENDPARECEIVEDCNT
  0x17C DEBUGDISCARDNDPCNT ro — WLAN MAC CTRL DEAGG DEBUG DISCARD NDP CNT
    [23:0] WLANMACCTRLDEAGGDEBUGDISCARDNDPCNT
  0x180 DEBUGHEMUAMPDUCNT ro — WLAN MAC CTRL DEAGG DEBUG HE MU AMPDU CNT
    [23:0] WLANMACCTRLDEAGGDEBUGHEMUAMPDUCNT
  0x184 DEBUGHESUAMPDUCNT ro — WLAN MAC CTRL DEAGG DEBUG HE SU AMPDU CNT
    [23:0] WLANMACCTRLDEAGGDEBUGHESUAMPDUCNT
  0x188 DEBUGRAMATCHEDHETPACKAMPDUCNT ro — WLAN MAC CTRL DEAGG DEBUG RA MATCHED HETP ACK AMPDU CNT
    [23:0] WLANMACCTRLDEAGGDEBUGRAMATCHEDHETPACKAMPDUCNT
  0x18C DEBUGSENDBAFORHETPACKAMPDUCNT ro — WLAN MAC CTRL DEAGG DEBUG SEND BA FOR HETP ACK AMPDU CNT
    [23:0] WLANMACCTRLDEAGGDEBUGSENDBAFORHETPACKAMPDUCNT
  0x190 DEBUGSENDBAFORNORMALACKPOLICYCNT ro — WLAN MAC CTRL DEAGG DEBUG SEND BA FOR NORMAL ACK POLICY CNT
    [23:0] WLANMACCTRLDEAGGDEBUGSENDBAFORNORMALACKPOLICYCNT
  0x194 DEBUGSENDBAFORBARCNT ro — WLAN MAC CTRL DEAGG DEBUG SEND BA FOR BAR CNT
    [23:0] WLANMACCTRLDEAGGDEBUGSENDBAFORBARCNT
  0x198 DEBUGSENDBAFORMUBARCNT ro — WLAN MAC CTRL DEAGG DEBUG SEND BA FOR MU BAR CNT
    [23:0] WLANMACCTRLDEAGGDEBUGSENDBAFORMUBARCNT
  0x19C DEBUGSENDHEBACNT ro — WLAN MAC CTRL DEAGG DEBUG SEND HE BA CNT
    [23:0] WLANMACCTRLDEAGGDEBUGSENDHEBACNT
  0x1A0 DEBUGSENDBACNT ro — WLAN MAC CTRL DEAGG DEBUG SEND BA CNT
    [23:0] WLANMACCTRLDEAGGDEBUGSENDBACNT
  0x1A4 DEBUGAMPDUSUBFRMCRC32PASSCNT ro — WLAN MAC CTRL DEAGG DEBUG AMPDU SUB FRM CRC32 PASS CNT
    [23:0] WLANMACCTRLDEAGGDEBUGAMPDUSUBFRMCRC32PASSCNT
  0x1A8 DEBUGAMPDUSUBFRMCRC32FAILCNT ro — WLAN MAC CTRL DEAGG DEBUG AMPDU SUB FRM CRC32 FAIL CNT
    [23:0] WLANMACCTRLDEAGGDEBUGAMPDUSUBFRMCRC32FAILCNT
  0x1AC DEBUGBITMAPRECORDB0TOB23 ro — WLAN MAC CTRL DEAGG DEBUG BITMAP RECORD B0 TO B23
    [23:0] WLANMACCTRLDEAGGDEBUGBITMAPRECORDB0TOB23
  0x1B0 DEBUGBITMAPRECORDB24TOB47 ro — WLAN MAC CTRL DEAGG DEBUG BITMAP RECORD B24 TO B47
    [23:0] WLANMACCTRLDEAGGDEBUGBITMAPRECORDB24TOB47
  0x1B4 DEBUGBITMAPRECORDB48TOB63 ro — WLAN MAC CTRL DEAGG DEBUG BITMAP RECORD B48 TO B63
    [15:0] WLANMACCTRLDEAGGDEBUGBITMAPRECORDB48TOB63
  0x1B8 DEBUGBITMAPRECORDSSN ro — WLAN MAC CTRL DEAGG DEBUG BITMAP RECORD SSN
    [11:0] WLANMACCTRLDEAGGDEBUGBITMAPRECORDSSN
  0x1BC DEBUGBARSSN ro — WLAN MAC CTRL DEAGG DEBUG BAR SSN
    [11:0] WLANMACCTRLDEAGGDEBUGBARSSN
  0x1C0 DEBUGBABITMAPB0TOB23 ro — WLAN MAC CTRL DEAGG DEBUG BA BITMAP B0 TO B23
    [23:0] WLANMACCTRLDEAGGDEBUGBABITMAPB0TOB23
  0x1C4 DEBUGBABITMAPB24TOB47 ro — WLAN MAC CTRL DEAGG DEBUG BA BITMAP B24 TO B47
    [23:0] WLANMACCTRLDEAGGDEBUGBABITMAPB24TOB47
  0x1C8 DEBUGBABITMAPB48TOB63 ro — WLAN MAC CTRL DEAGG DEBUG BA BITMAP B48 TO B63
    [15:0] WLANMACCTRLDEAGGDEBUGBABITMAPB48TOB63
  0x1CC DEBUGBASSN ro — WLAN MAC CTRL DEAGG DEBUG BA SSN
    [11:0] WLANMACCTRLDEAGGDEBUGBASSN
  0x1D0 DEBUGNAVBUSYDROPRTSCNT ro — WLAN MAC CTRL DEAGG DEBUG NAV BUSY DROP RTS CNT
    [23:0] WLANMACCTRLDEAGGDEBUGNAVBUSYDROPRTSCNT
  0x1D4 DEBUGNAVBUSYDROPBASICTRIGCNT ro — WLAN MAC CTRL DEAGG DEBUG NAV BUSY DROP BASIC TRIG CNT
    [23:0] WLANMACCTRLDEAGGDEBUGNAVBUSYDROPBASICTRIGCNT
  0x1D8 MAXWAITCNTINSIFS reset 0xFA0 — WLAN MAC CTRL DEAGG MAX WAIT CNT IN SIFS
    [15:0] WLANMACCTRLDEAGGMAXWAITCNTINSIFS
  0x1DC CSICTRLDATAFRAMES — WLAN MAC CTRL DEAGG CSI CTRL DATA FRAMES
    [16:0] WLANMACCTRLDEAGGCSICTRLDATAFRAMES
  0x1E0 CSICTRLMGMTFRAMES — WLAN MAC CTRL DEAGG CSI CTRL MGMT FRAMES
    [16:0] WLANMACCTRLDEAGGCSICTRLMGMTFRAMES
  0x1E4 CSICTRLCONTROLFRAMES — WLAN MAC CTRL DEAGG CSI CTRL CONTROL FRAMES
    [16:0] WLANMACCTRLDEAGGCSICTRLCONTROLFRAMES
  0x1E8 CSICTRL — WLAN MAC CTRL DEAGG CSI CTRL
    [3:0] WLANMACCTRLDEAGGCSICTRL
  0x1EC CSIEVENTCLR — WLAN MAC CTRL DEAGG CSI EVENT CLR
    [0] WLANMACCTRLDEAGGCSIEVENTCLR
  0x1F0 CSILOCKCLR — WLAN MAC CTRL DEAGG CSI LOCK CLR
    [0] WLANMACCTRLDEAGGCSILOCKCLR
  0x1F4 CSIBUFID ro — WLAN MAC CTRL DEAGG CSI BUF ID
    [2:0] WLANMACCTRLDEAGGCSIBUFID
  {0x1F8+4j} CSIBUF{j}AVLBL (j=0..3) — WLAN MAC CTRL DEAGG CSI BUF{j} AVLBL
    [23:0] WLANMACCTRLDEAGGCSIBUF{j}AVLBL
  0x208 CSIEVENTSTATUS ro — WLAN MAC CTRL DEAGG CSI EVENT STATUS
    [23:0] WLANMACCTRLDEAGGCSIEVENTSTATUS
  0x20C DTIMBEACONNOTRAFFICEVENTSTATUS ro — WLAN MAC CTRL DEAGG DTIM BEACON NO TRAFFIC EVENT STATUS
    [1:0] WLANMACCTRLDEAGGDTIMBEACONNOTRAFFICEVENTSTATUS
  0x210 DTIMBEACONNOTRAFFICEVENTCLR — WLAN MAC CTRL DEAGG DTIM BEACON NO TRAFFIC EVENT CLR
    [0] WLANMACCTRLDEAGGDTIMBEACONNOTRAFFICEVENTCLR
  0x214 BEACONRATEMCSMODULATIONTYPE ro — WLAN MAC CTRL DEAGG BEACON RATE MCS MODULATION TYPE
    [11:0] WLANMACCTRLDEAGGBEACONRATEMCSMODULATIONTYPE
  0x218 BEACONLEN ro — WLAN MAC CTRL DEAGG BEACON LEN
    [11:0] WLANMACCTRLDEAGGBEACONLEN
  0x21C BEACONTSFLSB ro — WLAN MAC CTRL DEAGG BEACON TSF LSB
    [23:0] WLANMACCTRLDEAGGBEACONTSFLSB
  0x220 BEACONTSFMIDSB ro — WLAN MAC CTRL DEAGG BEACON TSF MIDSB
    [23:0] WLANMACCTRLDEAGGBEACONTSFMIDSB
  0x224 BEACONTSFMSB ro — WLAN MAC CTRL DEAGG BEACON TSF MSB
    [15:0] WLANMACCTRLDEAGGBEACONTSFMSB
  0x228 BEACONDTIMCOUNT ro — WLAN MAC CTRL DEAGG BEACON DTIM COUNT
    [7:0] WLANMACCTRLDEAGGBEACONDTIMCOUNT
  0x22C BEACONDTIMPERIOD ro — WLAN MAC CTRL DEAGG BEACON DTIM PERIOD
    [7:0] WLANMACCTRLDEAGGBEACONDTIMPERIOD
  0x230 BEACONMULTICASTUNICASTCHECK — WLAN MAC CTRL DEAGG BEACON MULTICAST UNICAST CHECK
    [2:0] WLANMACCTRLDEAGGBEACONMULTICASTUNICASTCHECK
  0x234 BEACONFIXEDPARAMETERSLEN — WLAN MAC CTRL DEAGG BEACON FIXED PARAMETERS LEN
    [7:0] WLANMACCTRLDEAGGBEACONFIXEDPARAMETERSLEN
  0x3F8 DISCARDPKTEVENTSTATUS ro — WLAN MAC CTRL DEAGG DISCARD PKT EVENT STATUS
    [0] WLANMACCTRLDEAGGDISCARDPKTEVENTSTATUS
  0x3FC RXDMAEVENTSTATUS ro — WLAN MAC CTRL DEAGG RX DMA EVENT STATUS
    [0] WLANMACCTRLDEAGGRXDMAEVENTSTATUS
0x18000 WLAN_MAC_CTRL_AGG group — Unspecified
  0x00 PULSEDRESET — WLAN MAC CTRL AGG PULSED RESET
    [0] WLANMACCTRLAGGPULSEDRESET
  0x04 LATCHEDRESET — WLAN MAC CTRL AGG LATCHED RESET
    [0] WLANMACCTRLAGGLATCHEDRESET
  0x08 TXENABLE — WLAN MAC CTRL AGG TX ENABLE
    [0] WLANMACCTRLAGGTXENABLE
  0x0C BTCOEXENABLE — WLAN MAC CTRL AGG BT COEX ENABLE
    [3:0] WLANMACCTRLAGGBTCOEXENABLE
  0x10 PHYTXVECTORCNT — WLAN MAC CTRL AGG PHY TX VECTOR CNT
    [5:0] WLANMACCTRLAGGPHYTXVECTORCNT
  0x14 DMAEVENTSTATUS ro — WLAN MAC CTRL AGG DMA EVENT STATUS
    [23:0] WLANMACCTRLAGGDMAEVENTSTATUS
  0x18 DMAEVENTSTATUSCLEAR wo — WLAN MAC CTRL AGG DMA EVENT STATUS CLEAR
    [1:0] WLANMACCTRLAGGDMAEVENTSTATUSCLEAR
  0x1C TXFWEVENTSTATUS ro — WLAN MAC CTRL AGG TX FW EVENT STATUS
    [2:0] WLANMACCTRLAGGTXFWEVENTSTATUS — 0 : TX_SUCCESS1 : TX_BT_ABORT2 : TX_BT_ABORT_AT_END3 : TX_PHY_CCA_ABORT4 : TX_DMA_UNDERRUN5 : TX_ACK_TO
  0x20 TXEDCASTATUS ro — WLAN MAC CTRL AGG TX EDCA STATUS
    [23:0] WLANMACCTRLAGGTXEDCASTATUS
  0x24 TXFWEVENTSTATUSCLEAR wo — WLAN MAC CTRL AGG TX FW EVENT STATUS CLEAR
    [0] WLANMACCTRLAGGTXFWEVENTSTATUSCLEAR
  0x28 DSSSTXTOTXSIFS — WLAN MAC CTRL AGG DSSS TX TO TX SIFS
    [23:0] WLANMACCTRLAGGDSSSTXTOTXSIFS
  0x2C OFDMTXTOTXSIFS — WLAN MAC CTRL AGG OFDM TX TO TX SIFS
    [23:0] WLANMACCTRLAGGOFDMTXTOTXSIFS
  {0x30+4j} AC1TXVECTOR[{j}] (j=0..73) — Description collection: WLAN MAC CTRL AGG AC1 TX VECTOR
    [23:0] WLANMACCTRLAGGAC1TXVECTOR
  {0x158+4j} AC2TXVECTOR[{j}] (j=0..73) — Description collection: WLAN MAC CTRL AGG AC2 TX VECTOR
    [23:0] WLANMACCTRLAGGAC2TXVECTOR
  {0x280+4j} AC3TXVECTOR[{j}] (j=0..73) — Description collection: WLAN MAC CTRL AGG AC3 TX VECTOR
    [23:0] WLANMACCTRLAGGAC3TXVECTOR
  {0x3A8+4j} AC4TXVECTOR[{j}] (j=0..73) — Description collection: WLAN MAC CTRL AGG AC4 TX VECTOR
    [23:0] WLANMACCTRLAGGAC4TXVECTOR
  {0x4D0+4j} AC5TXVECTOR[{j}] (j=0..73) — Description collection: WLAN MAC CTRL AGG AC5 TX VECTOR
    [23:0] WLANMACCTRLAGGAC5TXVECTOR
  {0x5F8+4j} SIFSRESPTXVECTOR[{j}] (j=0..51) — Description collection: WLAN MAC CTRL AGG SIFS RESP TX VECTOR
    [23:0] WLANMACCTRLAGGSIFSRESPTXVECTOR
  {0x6C8+4j} SIFSFRAMERATETABLE[{j}] (j=0..57) — Description collection: WLAN MAC CTRL AGG SIFS FRAME RATE TABLE
    [23:0] WLANMACCTRLAGGSIFSFRAMERATETABLE
  {0x7B0+4j} HETBAC0TXVECTOR[{j}] (j=0..51) — Description collection: WLAN MAC CTRL AGG HE TB AC0 TX VECTOR
    [23:0] WLANMACCTRLAGGHETBAC0TXVECTOR
  {0x880+4j} HETBAC1TXVECTOR[{j}] (j=0..51) — Description collection: WLAN MAC CTRL AGG HE TB AC1 TX VECTOR
    [23:0] WLANMACCTRLAGGHETBAC1TXVECTOR
  {0x950+4j} HETBAC2TXVECTOR[{j}] (j=0..51) — Description collection: WLAN MAC CTRL AGG HE TB AC2 TX VECTOR
    [23:0] WLANMACCTRLAGGHETBAC2TXVECTOR
  {0xA20+4j} HETBAC3TXVECTOR[{j}] (j=0..51) — Description collection: WLAN MAC CTRL AGG HE TB AC3 TX VECTOR
    [23:0] WLANMACCTRLAGGHETBAC3TXVECTOR
  {0xAF0+4j} HETBAC{j}TXENABLE (j=0..3) — WLAN MAC CTRL AGG HE TB AC{j} TX ENABLE
    [0] WLANMACCTRLAGGHETBAC{j}TXENABLE
  0xB00 MPDUFRAMES ro — WLAN MAC CTRL AGG MPDU FRAMES
    [5:0] WLANMACCTRLAGGMPDUFRAMES
  0xB04 HTCTRLBSRPCAPABLE — WLAN MAC CTRL AGG HTCTRL BSRP CAPABLE
    [0] WLANMACCTRLAGGHTCTRLBSRPCAPABLE
  {0xB08+4j} HETBBSRPTXVECTOR[{j}] (j=0..51) — Description collection: WLAN MAC CTRL AGG HE TB BSRP TX VECTOR
    [23:0] WLANMACCTRLAGGHETBBSRPTXVECTOR
  {0xBD8+4j} HETBTID{j}TXENABLE (j=0..7) — WLAN MAC CTRL AGG HE TB TID{j} TX ENABLE
    [0] WLANMACCTRLAGGHETBTID{j}TXENABLE
  {0xBF8+4j} HETBTID{j}TXLENGTH (j=0..7) — WLAN MAC CTRL AGG HE TB TID{j} TX LENGTH
    [22:0] WLANMACCTRLAGGHETBTID{j}TXLENGTH
  0xC18 BEAMFORMGRAMPTR — WLAN MAC CTRL AGG BEAMFORM GRAM PTR
    [23:0] WLANMACCTRLAGGBEAMFORMGRAMPTR
  0xC1C BEAMFORMDMALENGTH ro — WLAN MAC CTRL AGG BEAMFORM DMA LENGTH
    [8:0] WLANMACCTRLAGGBEAMFORMDMALENGTH
  0xC24 WAITSTATE1TIME — WLAN MAC CTRL AGG WAIT STATE 1 TIME
    [19:0] WLANMACCTRLAGGWAITSTATE1TIME
  0xC28 TXPOWZEROTXGAIN — WLAN MAC CTRL AGG TXPOW ZERO TX GAIN
    [7:0] WLANMACCTRLAGGTXPOWZEROTXGAIN
  0xC2C TXPOWSTEP — WLAN MAC CTRL AGG TX POW STEP
    [4:0] WLANMACCTRLAGGTXPOWSTEP
  0xC30 TXPKTTIMESTAMP00 ro — WLAN MAC CTRL AGG TX PKT TIMESTAMP 0 0
    [23:0] WLANMACCTRLAGGTXPKTTIMESTAMP00
  0xC34 TXPKTTIMESTAMP01 ro — WLAN MAC CTRL AGG TX PKT TIMESTAMP 0 1
    [23:0] WLANMACCTRLAGGTXPKTTIMESTAMP01
  0xC38 TXPKTTIMESTAMP10 ro — WLAN MAC CTRL AGG TX PKT TIMESTAMP 1 0
    [23:0] WLANMACCTRLAGGTXPKTTIMESTAMP10
  0xC3C TXPKTTIMESTAMP11 ro — WLAN MAC CTRL AGG TX PKT TIMESTAMP 1 1
    [23:0] WLANMACCTRLAGGTXPKTTIMESTAMP11
  {0xC34+0xC*j} TXPKTTIMESTAMP{j}CTRL (j=1..4) — WLAN MAC CTRL AGG TX PKT TIMESTAMP {j} CTRL
    [0] WLANMACCTRLAGGTXPKTTIMESTAMP{j}CTRL
  0xC44 TXPKTTIMESTAMP20 ro — WLAN MAC CTRL AGG TX PKT TIMESTAMP 2 0
    [23:0] WLANMACCTRLAGGTXPKTTIMESTAMP20
  0xC48 TXPKTTIMESTAMP21 ro — WLAN MAC CTRL AGG TX PKT TIMESTAMP 2 1
    [23:0] WLANMACCTRLAGGTXPKTTIMESTAMP21
  0xC50 TXPKTTIMESTAMP30 ro — WLAN MAC CTRL AGG TX PKT TIMESTAMP 3 0
    [23:0] WLANMACCTRLAGGTXPKTTIMESTAMP30
  0xC54 TXPKTTIMESTAMP31 ro — WLAN MAC CTRL AGG TX PKT TIMESTAMP 3 1
    [23:0] WLANMACCTRLAGGTXPKTTIMESTAMP31
  0xC5C TXPKTTIMESTAMP40 ro — WLAN MAC CTRL AGG TX PKT TIMESTAMP 4 0
    [23:0] WLANMACCTRLAGGTXPKTTIMESTAMP40
  0xC60 TXPKTTIMESTAMP41 ro — WLAN MAC CTRL AGG TX PKT TIMESTAMP 4 1
    [23:0] WLANMACCTRLAGGTXPKTTIMESTAMP41
  0xC68 DISABLEMISCCOMPUTATIONS — WLAN MAC CTRL AGG DISABLE MISC COMPUTATIONS
    [7:0] WLANMACCTRLAGGDISABLEMISCCOMPUTATIONS
  {0xC6C+4j} MAXTXPWRMCS{j} (j=0..7) — WLAN MAC CTRL AGG MAX TX PWR MCS {j}
    [5:0] WLANMACCTRLAGGMAXTXPWRMCS{j}
  0xC8C DEBUGFSMSTATE ro — WLAN MAC CTRL AGG DEBUG FSM STATE
    [4:0] WLANMACCTRLAGGDEBUGFSMSTATE — Aggregation FSM State:
      0=TxIdle; 1=TxPreProc; 2=SendTxVector; 3=ProcessMpduPayload; 4=CalcAmpduDelimiter; 5=AppendCrc; 6=WaitForTxEnd; 7=AddPadBytes; 8=NullDelimiters; 9=WaitState; 10=WaitForSifs; 11=BeamformGramData; 12=ComputeTxPowLut; 13=COMPUTE_BASICTRIGGER_ULLENGTH; 14=PREP_BASICTRIGGER_ACLST; 15=PrepTriggerFrame; 16=COMPUTING_BASICTRIGGER_ULLENGTH; 17=InvalidUlBwOrRu; 18=BasictriggerNoData
  0xC90 DEBUGMPDUORAMPDU ro — WLAN MAC CTRL AGG DEBUG MPDU OR AMPDU
    [0] WLANMACCTRLAGGDEBUGMPDUORAMPDU
  0xC94 DEBUGMPDULENGTH ro — WLAN MAC CTRL AGG DEBUG MPDU LENGTH
    [23:0] WLANMACCTRLAGGDEBUGMPDULENGTH
  0xC98 DEBUGAMPDUCURRENTSUBFRAMELENGTH ro — WLAN MAC CTRL AGG DEBUG AMPDU CURRENT SUBFRAME LENGTH
    [13:0] WLANMACCTRLAGGDEBUGAMPDUCURRENTSUBFRAMELENGTH
  0xC9C DEBUGCURRENTMPDUPENDINGBYTES ro — WLAN MAC CTRL AGG DEBUG CURRENT MPDU PENDING BYTES
    [23:0] WLANMACCTRLAGGDEBUGCURRENTMPDUPENDINGBYTES
  0xCA0 DEBUGISPROTECTIONFRAME ro — WLAN MAC CTRL AGG DEBUG IS PROTECTION FRAME
    [0] WLANMACCTRLAGGDEBUGISPROTECTIONFRAME
  0xCA4 DEBUGCTSTIMEOUTVALUE ro — WLAN MAC CTRL AGG DEBUG CTS TIMEOUT VALUE
    [22:0] WLANMACCTRLAGGDEBUGCTSTIMEOUTVALUE
  0xCA8 DEBUGACKTIMEOUTVALUE ro — WLAN MAC CTRL AGG DEBUG ACK TIMEOUT VALUE
    [22:0] WLANMACCTRLAGGDEBUGACKTIMEOUTVALUE
  0xCAC DEBUGINSIFSFRAMETX ro — WLAN MAC CTRL AGG DEBUG IN SIFS FRAME TX
    [0] WLANMACCTRLAGGDEBUGINSIFSFRAMETX
  0xCB0 DEBUGSIFSRESPONSEFRAMETYPE ro — WLAN MAC CTRL AGG DEBUG SIFS RESPONSE FRAME TYPE
    [5:0] WLANMACCTRLAGGDEBUGSIFSRESPONSEFRAMETYPE
  0xCB4 DEBUGTXPOW ro — WLAN MAC CTRL AGG DEBUG TX POW
    [4:0] WLANMACCTRLAGGDEBUGTXPOW
  0xCB8 DEBUGBASICTRIGQOSFRMCNT ro — WLAN MAC CTRL AGG DEBUG BASIC TRIG QOS FRM CNT
    [15:0] WLANMACCTRLAGGDEBUGBASICTRIGQOSFRMCNT
  0xCBC DEBUGCOMMONINFO13 ro — WLAN MAC CTRL AGG DEBUG COMMON INFO 1 3
    [23:0] WLANMACCTRLAGGDEBUGCOMMONINFO13
  0xCC0 DEBUGCOMMONINFO46 ro — WLAN MAC CTRL AGG DEBUG COMMON INFO 4 6
    [23:0] WLANMACCTRLAGGDEBUGCOMMONINFO46
  0xCC4 DEBUGCOMMONINFO78 ro — WLAN MAC CTRL AGG DEBUG COMMON INFO 7 8
    [14:0] WLANMACCTRLAGGDEBUGCOMMONINFO78
  0xCC8 DEBUGUSERINFO13 ro — WLAN MAC CTRL AGG DEBUG USER INFO 1 3
    [23:0] WLANMACCTRLAGGDEBUGUSERINFO13
  0xCCC DEBUGUSERINFO45 ro — WLAN MAC CTRL AGG DEBUG USER INFO 4 5
    [14:0] WLANMACCTRLAGGDEBUGUSERINFO45
  0xCD0 DEBUGTRIGGERCNT ro — WLAN MAC CTRL AGG DEBUG TRIGGER CNT
    [23:0] WLANMACCTRLAGGDEBUGTRIGGERCNT
  0xCD4 DEBUGTRIGGERTYPE ro — WLAN MAC CTRL AGG DEBUG TRIGGER TYPE
    [3:0] WLANMACCTRLAGGDEBUGTRIGGERTYPE
  0xCD8 DEBUGBASICCNT ro — WLAN MAC CTRL AGG DEBUG BASIC CNT
    [23:0] WLANMACCTRLAGGDEBUGBASICCNT
  0xCDC DEBUGBSRPCNT ro — WLAN MAC CTRL AGG DEBUG BSRP CNT
    [23:0] WLANMACCTRLAGGDEBUGBSRPCNT
  0xCE0 DEBUGEDCACNT ro — WLAN MAC CTRL AGG DEBUG EDCA CNT
    [23:0] WLANMACCTRLAGGDEBUGEDCACNT
  0xCE4 DEBUGINVALIDBWCNT ro — WLAN MAC CTRL AGG DEBUG INVALID BW CNT
    [23:0] WLANMACCTRLAGGDEBUGINVALIDBWCNT
  0xCE8 DEBUGSENDBACNT ro — WLAN MAC CTRL AGG DEBUG SEND BA CNT
    [23:0] WLANMACCTRLAGGDEBUGSENDBACNT
  0xCEC DEBUGMUBARCNT ro — WLAN MAC CTRL AGG DEBUG MU BAR CNT
    [23:0] WLANMACCTRLAGGDEBUGMUBARCNT
  0xCF0 DEBUGVHTBEAMFORM ro — WLAN MAC CTRL AGG DEBUG VHT BEAM FORM
    [23:0] WLANMACCTRLAGGDEBUGVHTBEAMFORM
  0xCF4 DEBUGHEBEAMFORM ro — WLAN MAC CTRL AGG DEBUG HE BEAM FORM
    [23:0] WLANMACCTRLAGGDEBUGHEBEAMFORM
  0xCF8 DEBUGCTSPKTCNT ro — WLAN MAC CTRL AGG DEBUG CTS PKT CNT
    [23:0] WLANMACCTRLAGGDEBUGCTSPKTCNT
  0xCFC DEBUGMUCTSPKTCNT ro — WLAN MAC CTRL AGG DEBUG MU CTS PKT CNT
    [23:0] WLANMACCTRLAGGDEBUGMUCTSPKTCNT
  0xD00 DEBUGACKPKTCNT ro — WLAN MAC CTRL AGG DEBUG ACK PKT CNT
    [23:0] WLANMACCTRLAGGDEBUGACKPKTCNT
  0xD04 DEBUGSIFSRCVDCNT ro — WLAN MAC CTRL AGG DEBUG SIFS RCVD CNT
    [23:0] WLANMACCTRLAGGDEBUGSIFSRCVDCNT
  0xD08 DEBUGSIFSRESPCNT ro — WLAN MAC CTRL AGG DEBUG SIFS RESP CNT
    [23:0] WLANMACCTRLAGGDEBUGSIFSRESPCNT
  0xD0C TXPREPROCESSINGCNT reset 0x78 — WLAN MAC CTRL AGG TX PRE PROCESSING CNT
    [15:0] WLANMACCTRLAGGTXPREPROCESSINGCNT
  0xD10 LGDPDBYPASS — WLAN MAC CTRL AGG LG DPD BYPASS
    [15:0] WLANMACCTRLAGGLGDPDBYPASS
  0xD14 NONHEDPDBYPASS — WLAN MAC CTRL AGG NON HE DPD BYPASS
    [9:0] WLANMACCTRLAGGNONHEDPDBYPASS
  0xD18 HEDPDBYPASS — WLAN MAC CTRL AGG HE DPD BYPASS
    [9:0] WLANMACCTRLAGGHEDPDBYPASS
  0xD1C LGCFRBYPASS — WLAN MAC CTRL AGG LG CFR BYPASS
    [15:0] WLANMACCTRLAGGLGCFRBYPASS
  0xD20 NONHECFRBYPASS — WLAN MAC CTRL AGG NON HE CFR BYPASS
    [9:0] WLANMACCTRLAGGNONHECFRBYPASS
  0xD24 HECFRBYPASS — WLAN MAC CTRL AGG HE CFR BYPASS
    [9:0] WLANMACCTRLAGGHECFRBYPASS
  0xD28 LGPRECFRENABLE — WLAN MAC CTRL AGG LG PRECFR ENABLE
    [15:0] WLANMACCTRLAGGLGPRECFRENABLE
  0xD2C NONHEPRECFRENABLE — WLAN MAC CTRL AGG NON HE PRECFR ENABLE
    [9:0] WLANMACCTRLAGGNONHEPRECFRENABLE
  0xD30 HEPRECFRENABLE — WLAN MAC CTRL AGG HE PRECFR ENABLE
    [9:0] WLANMACCTRLAGGHEPRECFRENABLE
  0xD34 POSTRSFILTERCFG — WLAN MAC CTRL AGG POST RS FILTER CFG
    [11:0] WLANMACCTRLAGGPOSTRSFILTERCFG
  0xD38 HTPOSTRSFILTERCFG — WLAN MAC CTRL AGG HT POST RS FILTER CFG
    [4:0] WLANMACCTRLAGGHTPOSTRSFILTERCFG
  0xD3C CPERESIDUALCFO — WLAN MAC CTRL AGG CPE RESIDUAL CFO
    [15:0] WLANMACCTRLAGGCPERESIDUALCFO
  0xD40 DEBUGTOTALCFO ro — WLAN MAC CTRL AGG DEBUG TOTAL CFO
    [15:0] WLANMACCTRLAGGDEBUGTOTALCFO
  {0xD44+4j} AC{j}RETRY (j=0..4) — WLAN MAC CTRL AGG AC{j} RETRY
    [0] WLANMACCTRLAGGAC{j}RETRY
  0xFFC DEBUGCONTROLS — WLAN MAC CTRL AGG DEBUG CONTROLS
    [0] WLANMACCTRLAGGDEBUGFREEZEFSMDURINGPBUSWRITES
